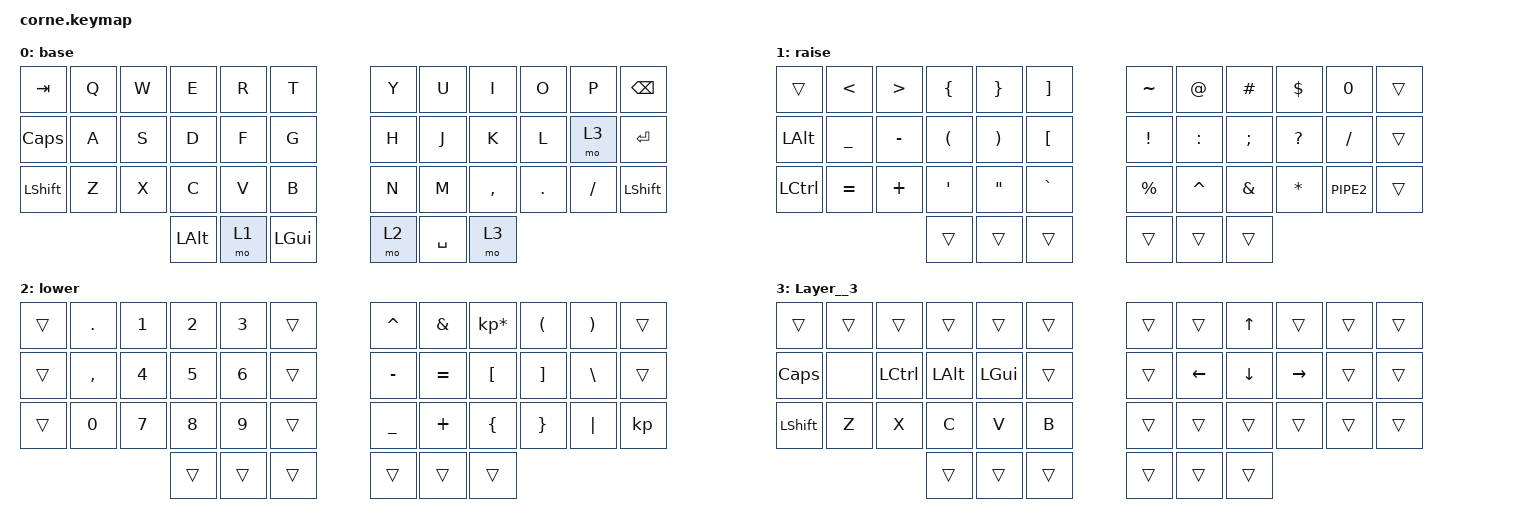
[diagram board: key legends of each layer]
/*
 * Copyright (c) 2020 The ZMK Contributors
 *
 * SPDX-License-Identifier: MIT
 */
/* THIS FILE WAS GENERATED!
 *
 * This file was generated automatically. You may or may not want to
 * edit it directly.
 */

#include <behaviors.dtsi>
#include <dt-bindings/zmk/keys.h>

/ {
    combos {
        compatible = "zmk,combos";

        tab {
            bindings = <&trans>;
            key-positions = <2 3>;
        };

        ctrl {
            bindings = <&kp LCTRL>;
            key-positions = <26 27>;
        };

        cmd {
            bindings = <&kp LCMD>;
            key-positions = <37 38>;
        };

        alt {
            bindings = <&kp LEFT_ALT>;
            key-positions = <39 40>;
        };

        shift {
            bindings = <&kp LSHIFT>;
            key-positions = <8 9>;
        };

        caps_word {
            bindings = <&caps_word>;
            key-positions = <17 18>;
        };

        delete {
            bindings = <&kp DEL>;
            key-positions = <32 33>;
        };
    };

    macros {
        zed_em_kay: zed_em_kay {
            compatible = "zmk,behavior-macro";
            label = "ZM_zed_em_kay";
            #binding-cells = <0>;
            bindings =
                <&macro_press>,
                <&kp LSHFT>,
                <&macro_tap>,
                <&kp Z &kp M &kp K>,
                <&macro_release>,
                <&kp LSHFT>;
        };
    };

    keymap {
        compatible = "zmk,keymap";

        base {
            bindings = <
   &kp TAB   &kp Q   &kp W     &kp E   &kp R     &kp T           &kp Y      &kp U      &kp I    &kp O     &kp P    &kp BSPC
  &kp CAPS   &kp A   &kp S     &kp D   &kp F     &kp G           &kp H      &kp J      &kp K    &kp L     &mo 3     &kp RET
 &kp LSHFT   &kp Z   &kp X     &kp C   &kp V     &kp B           &kp N      &kp M  &kp COMMA  &kp DOT  &kp FSLH  &kp LSHIFT
                            &kp LALT   &mo 1  &kp LGUI           &mo 2  &kp SPACE      &mo 3
            >;
        };

        raise {
            bindings = <
    &trans     &kp LT     &kp GT  &kp LBRC  &kp RBRC   &kp RBKT          &kp TILDE     &kp AT  &kp POUND   &kp DLLR     &kp N0  &trans
  &kp LALT  &kp UNDER  &kp MINUS  &kp LPAR  &kp RPAR   &kp LBKT           &kp EXCL  &kp COLON   &kp SEMI  &kp QMARK   &kp FSLH  &trans
 &kp LCTRL  &kp EQUAL   &kp PLUS   &kp SQT   &kp DQT  &kp GRAVE          &kp PRCNT  &kp CARET   &kp AMPS   &kp STAR  &kp PIPE2  &trans
                                    &trans    &trans     &trans             &trans     &trans     &trans
            >;
        };

        lower {
            bindings = <
 &trans    &kp DOT  &kp N1  &kp N2  &kp N3  &trans          &kp CARET   &kp AMPS  &kp KP_MULTIPLY  &kp LPAR  &kp RPAR  &trans
 &trans  &kp COMMA  &kp N4  &kp N5  &kp N6  &trans          &kp MINUS  &kp EQUAL         &kp LBKT  &kp RBKT  &kp BSLH  &trans
 &trans     &kp N0  &kp N7  &kp N8  &kp N9  &trans          &kp UNDER   &kp PLUS         &kp LBRC  &kp RBRC  &kp PIPE     &kp
                            &trans  &trans  &trans             &trans     &trans           &trans
            >;
        };

        Layer__3 {
            bindings = <
    &trans  &trans     &trans    &trans    &trans  &trans          &trans    &trans    &kp UP     &trans  &trans  &trans
  &kp CAPS   &none  &kp LCTRL  &kp LALT  &kp LGUI  &trans          &trans  &kp LEFT  &kp DOWN  &kp RIGHT  &trans  &trans
 &kp LSHFT   &kp Z      &kp X     &kp C     &kp V   &kp B          &trans    &trans    &trans     &trans  &trans  &trans
                                 &trans    &trans  &trans          &trans    &trans    &trans
            >;
        };
    };
};
